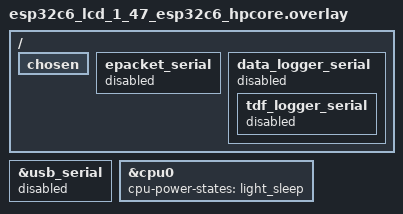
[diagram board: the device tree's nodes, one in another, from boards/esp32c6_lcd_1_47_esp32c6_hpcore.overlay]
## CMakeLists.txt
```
# Copyright (c) 2026 Embeint Holdings Pty Ltd
# SPDX-License-Identifier: FSL-1.1-ALv2

cmake_minimum_required(VERSION 3.20.0)
find_package(Zephyr REQUIRED HINTS $ENV{ZEPHYR_BASE})
project(infuse_display)
target_sources(app PRIVATE src/main.c)
```

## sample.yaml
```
sample:
  name: Infuse display
  description: Display the Infuse identity and uptime on LCD or e-paper panels
common:
  sysbuild: true
  build_only: true
  required_snippets:
    - infuse
  tags:
    - display
  filter: dt_chosen_enabled("zephyr,display")
tests:
  sample.display:
    integration_platforms:
      - esp32c6_lcd_1_47/esp32c6/hpcore
      - esp32c6_lcd_1_47/esp32c6/hpcore/flash8m
  sample.display.epaper:
    platform_allow:
      - nrf52840dk/nrf52840
    integration_platforms:
      - nrf52840dk/nrf52840
    extra_args:
      - SHIELD=waveshare_epaper_gdeh0213b1
```

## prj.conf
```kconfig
CONFIG_INFUSE_SDK=y
CONFIG_DISPLAY=y
CONFIG_LVGL=y
CONFIG_LV_USE_LABEL=y
CONFIG_LV_FONT_MONTSERRAT_14=y
CONFIG_LV_Z_MEM_POOL_SIZE=16384
CONFIG_LV_Z_VDB_SIZE=10
CONFIG_MAIN_STACK_SIZE=4096

# Display operation does not require a console, shell, or radio connection.
# Leave Infuse's system and runtime-device power management defaults enabled.
CONFIG_CONSOLE=n
CONFIG_UART_CONSOLE=n
CONFIG_LOG_BACKEND_UART=n
CONFIG_SHELL=n
CONFIG_BT=n
```

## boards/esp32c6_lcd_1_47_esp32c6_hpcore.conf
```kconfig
CONFIG_ESP_USB_SERIAL_JTAG_ENABLED=n
CONFIG_PWM=y
CONFIG_LED=y
```

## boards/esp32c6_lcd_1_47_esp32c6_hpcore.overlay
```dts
/* SPDX-License-Identifier: FSL-1.1-ALv2 */

/ {
	chosen {
		/delete-property/ zephyr,console;
		/delete-property/ zephyr,shell-uart;
	};

	epacket_serial {
		status = "disabled";
	};

	data_logger_serial {
		status = "disabled";
		tdf_logger_serial {
			status = "disabled";
		};
	};
};

&usb_serial {
	status = "disabled";
};

&cpu0 {
	cpu-power-states = <&light_sleep>;
};
```

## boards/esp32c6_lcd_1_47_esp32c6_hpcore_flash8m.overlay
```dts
/* SPDX-License-Identifier: FSL-1.1-ALv2 */
#include "esp32c6_lcd_1_47_esp32c6_hpcore.overlay"
```

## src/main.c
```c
/*
 * Copyright (c) 2026 Embeint Holdings Pty Ltd
 * SPDX-License-Identifier: FSL-1.1-ALv2
 */

#include <lvgl.h>
#include <zephyr/device.h>
#include <zephyr/drivers/display.h>
#include <zephyr/drivers/led.h>
#include <zephyr/kernel.h>
#include <zephyr/logging/log.h>

#include <infuse/identifiers.h>

LOG_MODULE_REGISTER(app, LOG_LEVEL_INF);

int main(void)
{
	const struct device *display = DEVICE_DT_GET(DT_CHOSEN(zephyr_display));
	struct display_capabilities capabilities;
	lv_obj_t *label;
	uint32_t refresh_ms;
	int rc;

	if (!device_is_ready(display)) {
		return -ENODEV;
	}
	display_get_capabilities(display, &capabilities);
	/* E-paper updates are expensive; avoid the LCD's continuously ticking UI. */
	refresh_ms = capabilities.screen_info & SCREEN_INFO_EPD ? 60000 : 1000;

#if DT_NODE_HAS_STATUS(DT_ALIAS(display_backlight), okay)
	const struct device *backlight = DEVICE_DT_GET(DT_PARENT(DT_ALIAS(display_backlight)));

	if (!device_is_ready(backlight)) {
		return -ENODEV;
	}
	rc = led_set_brightness(backlight, DT_NODE_CHILD_IDX(DT_ALIAS(display_backlight)), 25);
	if (rc != 0) {
		return rc;
	}
#endif

	/* Monochrome styling is readable on both colour LCD and e-paper panels. */
	lv_obj_set_style_bg_color(lv_screen_active(), lv_color_white(), 0);
	lv_obj_set_style_text_color(lv_screen_active(), lv_color_black(), 0);
	label = lv_label_create(lv_screen_active());
	lv_obj_set_width(label, capabilities.x_resolution);
	lv_obj_set_style_text_align(label, LV_TEXT_ALIGN_CENTER, 0);
	lv_obj_align(label, LV_ALIGN_CENTER, 0, 0);

	while (true) {
		lv_label_set_text_fmt(label, "Infuse-IoT\n\n%016llX\n\nUptime %lld s",
				      (unsigned long long)infuse_device_id(),
				      (long long)k_uptime_seconds());
		lv_timer_handler();
		rc = display_blanking_off(display);
		if (rc != 0 && rc != -ENOSYS) {
			return rc;
		}
		/* No animation or busy polling; idle time is available to the PM policy. */
		k_sleep(K_MSEC(refresh_ms));
	}
	return 0;
}
```
